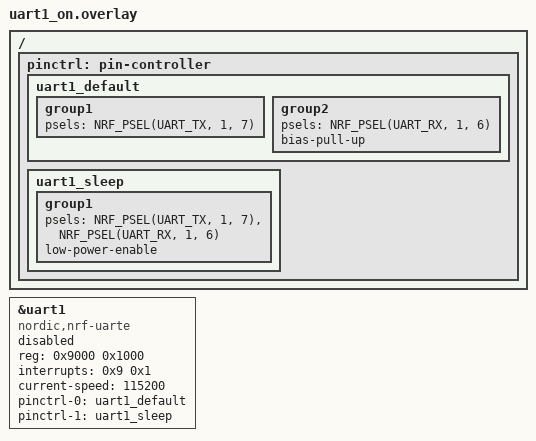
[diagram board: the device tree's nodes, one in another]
/ {
	pinctrl: pin-controller {
		uart1_default: uart1_default {
			group1 {
				psels = <NRF_PSEL(UART_TX, 1, 7)>;
			};
			group2 {
				psels = <NRF_PSEL(UART_RX, 1, 6)>;
				bias-pull-up;
			};
		};

		uart1_sleep: uart1_sleep {
			group1 {
				psels = <NRF_PSEL(UART_TX, 1, 7)>,
						<NRF_PSEL(UART_RX, 1, 6)>;
				low-power-enable;
			};
		};
	};
};

&uart1 {
	compatible = "nordic,nrf-uarte";
	reg = < 0x9000 0x1000 >;
	interrupts = < 0x9 0x1 >;
	status = "disabled";
	current-speed = <115200>;
	pinctrl-0 = <&uart1_default>;
	pinctrl-1 = <&uart1_sleep>;
	pinctrl-names = "default", "sleep";
};

